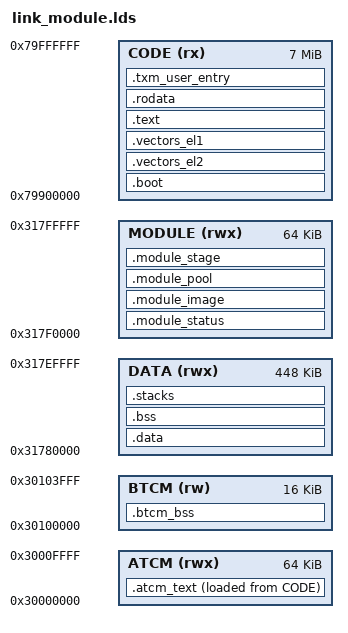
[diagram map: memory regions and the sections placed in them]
/***************************************************************************
 * Copyright (c) 2026 Eclipse ThreadX contributors
 *
 * This program and the accompanying materials are made available under the
 * terms of the MIT License which is available at
 * https://opensource.org/licenses/MIT.
 *
 * AI Disclosure: This file was largely AI-generated by Claude Code (Opus 5).
 * The AI-generated portions may be considered public domain (CC0-1.0)
 * and not subject to the project's licence. The human contributor has
 * reviewed and verified that the code is correct.
 *
 * SPDX-License-Identifier: MIT and CC0-1.0
 **************************************************************************/

/* Link map for the NXP S32Z280-594EVB, RTU0 core 0.
 *
 * Code goes to the RTU code SRAM at its instruction-fetch address, 0x79900000,
 * which is also where the core resets: MC_ME_PRTN0_CORE0_ADDR reads 0x79900000
 * on this board, so a debugger-loaded image needs no relocation to be reached
 * by the reset vector.  That window is writable over the debug AXI port even
 * though NXP's debugger memory map declares it read-only, so plain `load`
 * works and no LMA alias is required.  A flash-booted image is different: it
 * would have to be written through the data alias at 0x32100000.
 *
 * Data, bss and the per-mode stacks go to the RTU-local data SRAM at
 * 0x31780000.  Keeping them out of the code SRAM avoids the boundary problem
 * the FVP build hit, where an aligned .data start straddled the code/data
 * split, and RTU-local traffic does not leave the RTU.
 *
 * The TCMs are deliberately unused: they are not accessible at reset until
 * their region registers are programmed, so nothing needed for early boot can
 * live there.
 */

__hyp_stack_size__ = 0x0800;
__svc_stack_size__ = 0x1000;
__irq_stack_size__ = 0x0800;
__fiq_stack_size__ = 0x0400;
__abt_stack_size__ = 0x0400;
__und_stack_size__ = 0x0400;
__sys_stack_size__ = 0x0800;

MEMORY
{
    CODE (rx)  : ORIGIN = 0x79900000, LENGTH = 0x00700000    /* 7 MB   */
    /* ATCM.  entry.S programmes IMP_ATCMREGIONR to this base and enables the
       bank before anything runs from it, and mpu.c maps it executable.  Code
       placed here runs at full core speed with one wait state, where CODE is
       RTU code RAM and runs at half the core frequency (S32Z2 RM 6.3.6).  */
    ATCM (rwx) : ORIGIN = 0x30000000, LENGTH = 0x00010000    /* 64 KB  */
    /* BTCM.  16 KB at zero wait states, enabled by entry.S, and preloaded there
       as well because ECC means a location must be written before it is read.
       Used for data that wants deterministic access without depending on a
       cache -- an enabled TCM is never cached.  */
    BTCM (rw)  : ORIGIN = 0x30100000, LENGTH = 0x00004000    /* 16 KB  */
    DATA (rwx) : ORIGIN = 0x31780000, LENGTH = 0x00070000    /* 448 KB: DRAM0 + DRAM1 below the module area */
    /* Module memory, uncovered by any kernel MPU region on purpose.  See
       S32Z_MODULE_AREA_BASE in platform.h.  */
    MODULE (rwx) : ORIGIN = 0x317F0000, LENGTH = 0x00010000    /* 64 KB   */
}

ENTRY(_start)

SECTIONS
{
    /* .text.boot must come FIRST: MC_ME_PRTN0_CORE0_ADDR is 0x79900000 on
     * this board, so whatever lands at the start of CODE is what the core
     * executes out of reset, and that has to be _start.  It must also be a
     * T32 instruction, since the core resets in Thumb state.  The vector
     * tables need alignment but not a fixed address, because HVBAR and VBAR
     * are programmed at run time -- so they follow rather than lead.
     */
    /* No ALIGN() address expression on any output section below.  Written as
     * "<name> ALIGN(n) : { }" the ALIGN is the section's *address*, evaluated
     * from a location counter that starts at zero, and it silently overrides
     * "> CODE" -- every section then lands near address 0 and the link fails
     * with "not within region".  The FVP script uses that form harmlessly only
     * because its region starts at 0x00000000.  Alignment comes from the input
     * sections (the vector tables carry .align 5) or from an explicit
     * ". = ALIGN(n);" inside the braces.
     */
    .boot :
    {
        KEEP(*(.text.boot))
    } > CODE

    .vectors_el2 :
    {
        KEEP(*(.vectors_el2))
    } > CODE

    .vectors_el1 :
    {
        KEEP(*(.vectors_el1))
    } > CODE

    /* The shared granules the module reports its progress through, and the one
       it is not allowed to reach.

       FIRST in the module area, so the base address is ORIGIN(MODULE) and the
       module can carry it as a constant -- the manager deliberately knows no
       symbol of the module and has no channel through which to tell it anything.
       S32Z_MODULE_STATUS_BASE in platform.h is the same number, and the ASSERTs
       at the bottom of this file pin the two together at link time.

       Six granules.  Five are granted, one per shared entry the port provides,
       because granting a single region only ever exercises the first of the five;
       the sixth -- index 2, so a granted granule sits on either side of it -- is
       never granted, and the module writes it to prove it still faults.

       NOLOAD: the manager clears the area before every pass, and a granule that
       arrived pre-filled would make a module that never wrote one look as though
       it had.  */

    .module_status (NOLOAD) :
    {
        __module_status_start__ = .;
        . = . + 0x180;                  /* six 64-byte granules */
        . = ALIGN(64);
        __module_status_end__ = .;
    } > MODULE

    /* The module image, in the module area, just above the shared granules.

       The module is not linked here.  It is built as its own image by the
       s32z280_demo_module.elf target, objcopied to a raw binary and included as
       bytes by module_blob.S, and this section only decides where those bytes
       land.  Which address that is does not matter any more: since the module
       became relocatable it is linked against nominal addresses it never runs
       at and _gcc_setup rebases it to wherever it was put, so this only has to
       be inside the module area and disjoint from everything else in it.

       The earlier arrangement compiled the module's sources into this image and
       gathered them here by object name.  That cannot work.  The module library
       defines shims named after the same ThreadX entry points the kernel
       defines, and in a single link the shims win, because they arrive as
       objects and the kernel arrives as a static library.  The manager's own
       tx_thread_create resolved to the module's copy at 0x317F1700, called into
       the module area that no kernel region covers, and took a silent prefetch
       abort before the first thread ever ran.

       Keeping the module out of the link also removes a whole class of quiet
       failure that arrangement had: matching input sections by object-file name
       fails open.  A missing suffix or a wildcard that does not match produces an
       empty section, a link that succeeds and an image with no module in it,
       twice over here -- and the block had to sit before .text, because
       placement is first match and the kernel's *(.text*) would otherwise
       swallow the module's code while leaving its data behind.

       This block still sits before .text: harmless now, and it keeps the module
       at the head of the map where it is easy to find.  */

    .module_image :
    {
        __module_image_start__ = .;
        KEEP(*(.module_blob))
        . = ALIGN(64);
        __module_image_end__ = .;
    } > MODULE

    /* The pool the manager allocates module data from, in the module area for
       the same reason the image is: whatever the manager hands to a module
       becomes an MPU region, and PMSAv8-R will not allow that region to overlap
       a kernel one.  Anything a module can be given has to live outside every
       region in the boot table, and this area is the only such memory.

       NOLOAD because nothing is copied in -- the byte pool writes its own
       headers when it is created.  */

    .module_pool (NOLOAD) :
    {
        . = ALIGN(64);
        __module_pool_start__ = .;
        *(.module_pool)
        . = ALIGN(64);
        __module_pool_end__ = .;
    } > MODULE

    /* A second place to load the same module from, which is how this example
       proves the module is relocatable rather than merely built to be.

       A module that runs correctly at the address it was linked for proves
       nothing about relocation -- the GOT rebase would produce the same
       addresses it started with and a broken rebase would look identical.  So
       the manager copies the blob here and loads it a second time, and the two
       runs are compared.  Any address in the module area would do; what matters
       is that it is not __module_image_start__ and that it does not overlap the
       pool, because the code region of the second instance and the data regions
       the pool hands out are live at the same time and PMSAv8-R does not permit
       two enabled regions to overlap.

       NOLOAD, and deliberately not initialised at link time: if the blob were
       placed here by the linker as well, a failure to copy it would be invisible
       because the right bytes would already be present.  */

    .module_stage (NOLOAD) :
    {
        . = ALIGN(64);
        __module_stage_start__ = .;
        . = . + 0x1000;
        . = ALIGN(64);
        __module_stage_end__ = .;
    } > MODULE

    /* The code and data sizes are not computed here any more.  They belong to
       the module's own link, which is where its preamble is assembled and where
       the boundary between its code and its data is actually known.  */

    .text :
    {
        *(.text*)
        *(.glue_7)
        *(.glue_7t)
    } > CODE

    /* Code that runs from tightly-coupled memory.  Loaded into CODE and copied
       to ATCM by atcm_copy_text() before it is called, because ECC is enabled
       on this part and a TCM location must be written before it is read
       (Cortex-R52 TRM 6.2.2).  The copy uses 64-bit stores for the same
       reason: ATCM requires them where BTCM and CTCM accept 32-bit.

       ALIGN(8) at both ends so the copy can move whole 64-bit units without a
       tail case, which is what keeps the ECC requirement satisfied for every
       location written.  */

    .atcm_text : ALIGN(8)
    {
        __atcm_text_start__ = .;
        *(.atcm_text*)
        . = ALIGN(8);
        __atcm_text_end__ = .;
    } > ATCM AT> CODE

    __atcm_text_load__ = LOADADDR(.atcm_text);

    .rodata :
    {
        *(.rodata*)
        . = ALIGN(4);
        __code_end__ = .;
    } > CODE

    /* The module's gateway into the kernel, deliberately after __code_end__ and
       therefore outside the kernel code region, which ends there.  A module gets
       its own region covering exactly this function; that region would otherwise
       overlap the kernel's, which PMSAv8-R does not allow.

       Alone in its own section on purpose: anything sharing it would become
       executable by every module.  64-byte aligned at both ends, the PMSAv8-R
       granule, so a region can start and stop on it without covering
       neighbours.  */

    .txm_user_entry : ALIGN(64)
    {
        __txm_user_entry_start__ = .;
        KEEP(*(.txm_user_entry))
        . = ALIGN(64);
        __txm_user_entry_end__ = .;
    } > CODE

    .data :
    {
        . = ALIGN(8);
        __data_start__ = .;
        *(.data*)
        . = ALIGN(8);
        __data_end__ = .;
    } > DATA

    /* Data placed in BTCM.  NOLOAD: nothing is copied in, and entry.S has
       already written every location in the bank to establish ECC check bits,
       so anything here is safe to read before it is written by the program.  */

    .btcm_bss (NOLOAD) : ALIGN(8)
    {
        __btcm_bss_start__ = .;
        *(.btcm_bss*)
        . = ALIGN(8);
        __btcm_bss_end__ = .;
    } > BTCM

    .bss (NOLOAD) :
    {
        . = ALIGN(8);
        __bss_start__ = .;
        *(.bss*)
        *(COMMON)
        . = ALIGN(8);
        __bss_end__ = .;
    } > DATA

    /* Per-mode stacks.  Each mode needs its own on an R-profile core: an
     * exception taken while a handler is running would otherwise reuse the
     * interrupted mode's stack pointer.
     */
    .stacks (NOLOAD) :
    {
        . = ALIGN(8);
        . = . + __hyp_stack_size__;
        __hyp_stack_top = .;
        . = ALIGN(8);
        . = . + __svc_stack_size__;
        __svc_stack_top = .;
        . = ALIGN(8);
        . = . + __irq_stack_size__;
        __irq_stack_top = .;
        . = ALIGN(8);
        . = . + __fiq_stack_size__;
        __fiq_stack_top = .;
        . = ALIGN(8);
        . = . + __abt_stack_size__;
        __abt_stack_top = .;
        . = ALIGN(8);
        . = . + __und_stack_size__;
        __und_stack_top = .;
        . = ALIGN(8);
        . = . + __sys_stack_size__;
        __sys_stack_top = .;
    } > DATA

    /* Both spellings: _tx_initialize_low_level publishes the first free
       address to tx_application_define from _end, while C library conventions
       use end.  */

    PROVIDE(end = .);
    PROVIDE(_end = .);

    /* The module carries the status base as a constant and platform.h names it
       as S32Z_MODULE_STATUS_BASE.  Neither can see this script, so the agreement
       is pinned here; the manager checks the same thing again at run time
       against the symbol, so a build that skipped this file still says so.  */

    ASSERT(__module_status_start__ == 0x317F0000,
           "the module status area is not at S32Z_MODULE_STATUS_BASE")

    /* And its size: the manager grants one region per granule from that base and
       the module addresses them by index, so an area that is not exactly
       S32Z_MODULE_STATUS_GRANULES granules long would leave a grant, or a module
       write, outside it.  */

    ASSERT(__module_status_end__ - __module_status_start__ == 0x180,
           "the module status area is not S32Z_MODULE_STATUS_GRANULES granules long")
}
